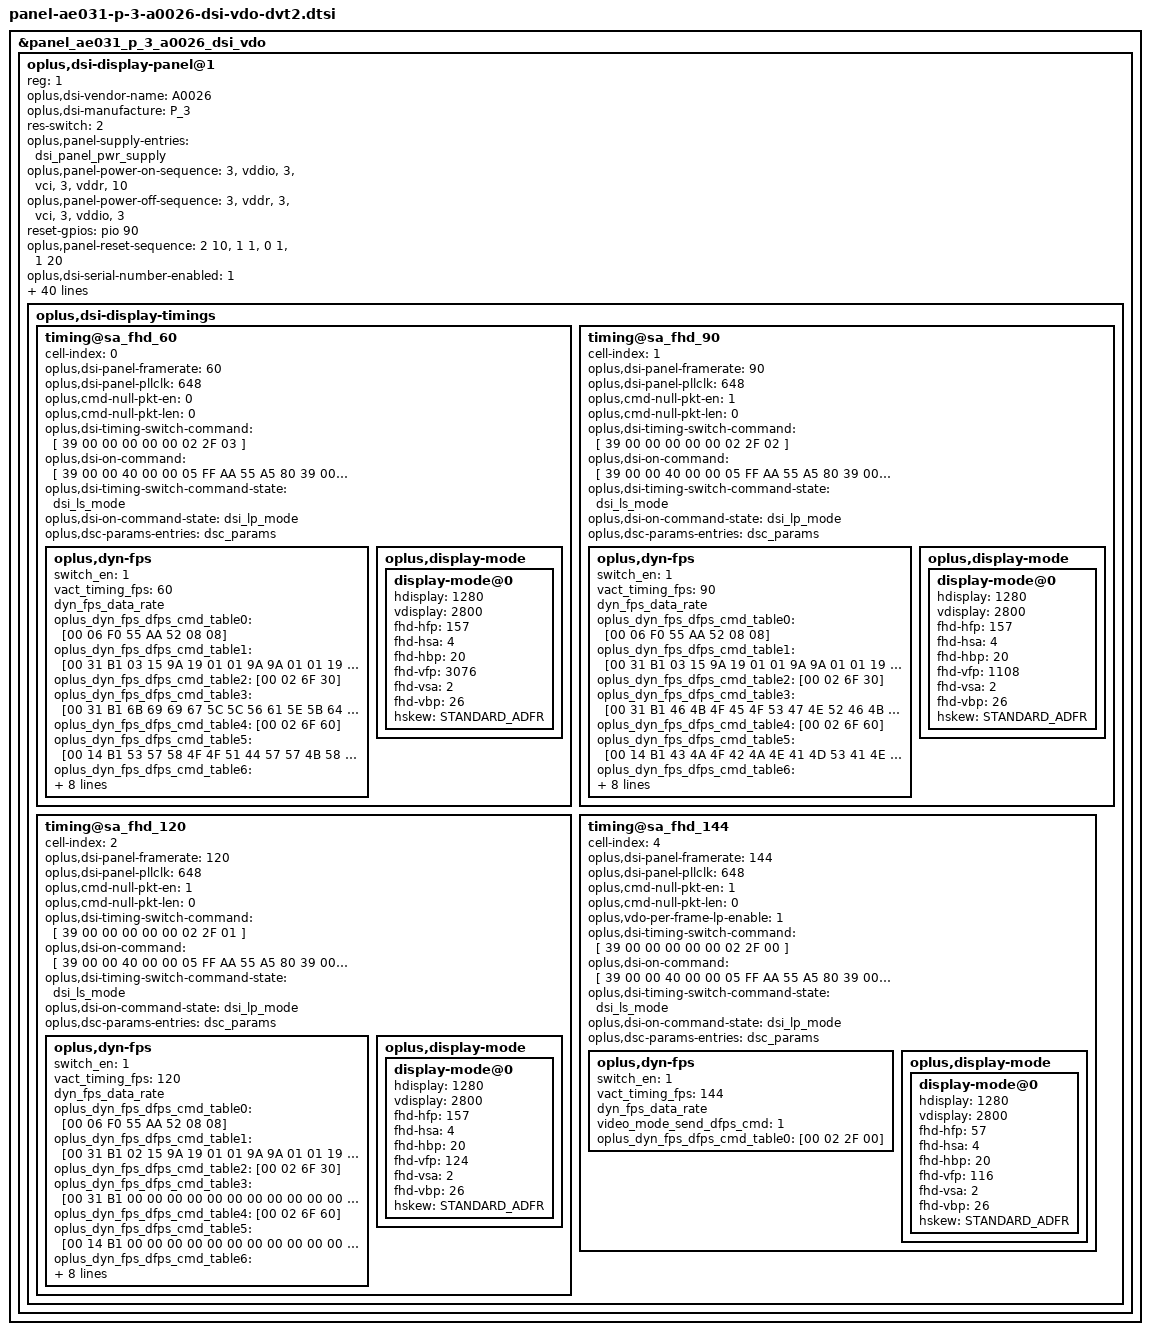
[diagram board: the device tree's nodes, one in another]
&panel_ae031_p_3_a0026_dsi_vdo {
	oplus,dsi-display-panel@1 {
		reg = <1>;
		oplus,dsi-vendor-name = "A0026";
		oplus,dsi-manufacture = "P_3";
		oplus,dsi-display-timings {
			timing@sa_fhd_60 {
				cell-index = <0>;
				oplus,dsi-panel-framerate = <60>;
				oplus,dsi-panel-pllclk = <648>;
				oplus,cmd-null-pkt-en = <0>;
				oplus,cmd-null-pkt-len = <0>;
				/* OPLUS_FEATURE_DISPLAY_ONSCREENFINGERPRINT */
				//oplus,ofp_need_keep_apart_backlight;
				#include "panel-ae031-p-3-a0026-dsi-vdo-common-dvt2.dtsi"
				oplus,dsi-timing-switch-command = [
					39 00 00 00 00 00 02 2F 03
				];

				oplus,dsi-on-command = [
					//Video trim OSC2 to 167Mhz
					//For other setting refer OP manual Ch 4.3
					39 00 00 40 00 00 05 FF AA 55 A5 80
					39 00 00 40 00 00 02 6F 0A
					39 00 00 40 00 00 02 F8 02
					39 00 00 40 00 00 06 F0 55 AA 52 08 01
					39 00 00 40 00 00 02 6F 04
					39 00 00 40 00 00 02 C3 FF
					39 00 00 40 00 00 02 6F 09
					39 00 00 40 00 00 02 C3 FF
					39 00 00 40 00 00 02 EA C0
					39 00 00 40 00 00 02 6F 11
					39 00 00 40 00 00 02 EA C0
					39 00 00 40 00 00 02 6F 07
					39 00 00 40 00 00 0B EA 01 02 01 34 01 34 01 34 04 D1
					39 00 00 40 00 00 02 6F 18
					39 00 00 40 00 00 0B EA 01 8A 01 D7 01 D7 01 D7 07 5E

					//VGXP by pad cap
					39 00 00 40 00 00 05 FF AA 55 A5 80
					39 00 00 40 00 00 02 6F 1F
					39 00 00 40 00 00 02 F4 0B
					39 00 00 40 00 00 02 6F 20
					39 00 00 40 00 00 02 F4 3F
					39 00 00 40 00 00 02 6F 08
					39 00 00 40 00 00 02 FC 03
					39 00 00 40 00 00 05 FF AA 55 A5 80
					39 00 00 40 00 00 02 6F 24
					39 00 00 00 00 00 02 F8 FF

					// For Idle enter BIST
					39 00 00 40 00 00 06 F0 55 AA 52 08 00
					39 00 00 40 00 00 02 C0 00
					39 00 00 40 00 00 06 F0 55 AA 52 08 01
					39 00 00 40 00 00 02 6F 0B
					39 00 00 40 00 00 02 D2 00
					39 00 00 40 00 00 05 FF AA 55 A5 84
					39 00 00 40 00 00 02 6F 10
					39 00 00 40 00 00 02 F8 02
					39 00 00 40 00 00 05 FF AA 55 A5 84
					39 00 00 40 00 00 02 F2 15

					//LCTC Constraint For ESD Improve
					39 00 00 40 00 00 05 FF AA 55 A5 84
					39 00 00 40 00 00 02 6F A9
					39 00 00 40 00 00 02 F4 F3

					//CUC OFF
					39 00 00 40 00 00 06 F0 55 AA 52 08 08
					39 00 00 40 00 00 02 B1 02
					//Resolution Setting
					39 00 00 40 00 00 05 2A 00 00 04 FF
					39 00 00 40 00 00 05 2B 00 00 0A EF

					//VESA1.2 10 bit 3.75 DSC Setting
					// For other refer OP manual Ch 4.4
					39 00 00 40 00 00 02 90 03
					39 00 00 40 00 00 02 6F 01
					39 00 00 40 00 00 02 90 43
					39 00 00 40 00 00 13 91 AB A8 00 28 D2 00 02 5C 04 06 00 08 02 AB 02 20 10 E0

					//Dimming OFF
					39 00 00 40 00 00 02 53 20

					//Video Mode Ext_VFP VBPF Setting
					39 00 00 40 00 00 11 3B 00 1c 00 74 00 1c 00 7C 00 1c 04 54 00 1c 00 7C
					39 00 00 40 00 00 02 6F 10
					39 00 00 40 00 00 05 3B 00 1C 00 7C

					//DPC Temperature Setting
					39 00 00 40 00 00 03 81 01 19

					//FPR1 EN
					39 00 00 40 00 00 02 88 01

					//60Hz Sleep Out
					//For other refer OP manual Ch 5.4.3
					39 00 00 40 00 00 02 2F 03

					//TE ON
					39 00 00 40 00 00 02 35 00

					//Setting Loading Effect x1.0
					39 00 00 40 00 00 03 5F 00 00

					39 00 00 40 00 00 06 F0 55 AA 52 08 00
					39 00 00 40 00 00 02 6F 03
					39 00 00 40 00 00 02 B5 D5

					//Switch DBV to 0560
					39 00 00 00 00 00 03 51 05 60
					05 00 00 00 78 00 01 11 // Sleep out
					05 00 00 00 00 00 01 29 // Display out
				];

				oplus,dsi-timing-switch-command-state = "dsi_ls_mode";
				oplus,dsi-on-command-state = "dsi_lp_mode";

				oplus,dsc-params-entries = <&dsc_params>;
				oplus,dyn-fps {
					switch_en = <1>;
					vact_timing_fps = <60>;
					dyn_fps_data_rate;
					oplus_dyn_fps_dfps_cmd_table0 = [00 06 F0 55 AA 52 08 08];
					oplus_dyn_fps_dfps_cmd_table1 = [00 31 B1 03 15 9A 19 01 01 9A 9A 01 01 19 19 20 20 4E 30 01 82 43 82 40 84 40 00 00 00 00 10 F1 E2 F1 E2 FF 44 4A 45 59 00 13 10 64 64 5F 6B 6A 67 6C 6B];
					oplus_dyn_fps_dfps_cmd_table2 = [00 02 6F 30];
					oplus_dyn_fps_dfps_cmd_table3 = [00 31 B1 6B 69 69 67 5C 5C 56 61 5E 5B 64 62 5F 60 5E 5C 5A 58 55 5C 5B 56 5C 5B 57 56 54 51 55 53 4D 55 52 50 54 52 4E 5D 5C 54 53 51 49 57 57 4E 5B 5B];
					oplus_dyn_fps_dfps_cmd_table4 = [00 02 6F 60];
					oplus_dyn_fps_dfps_cmd_table5 = [00 14 B1 53 57 58 4F 4F 51 44 57 57 4B 58 58 4C 54 54 48 00 00 00];
					oplus_dyn_fps_dfps_cmd_table6 = [00 31 B2 1F 1A 21 20 1C 26 24 1F 26 27 22 29 14 0E 17 13 0E 14 10 09 13 09 03 0C 1D 19 21 23 21 21 22 1F 23 24 22 21 1F 18 1E 20 1A 1F 21 1D 22 20 1A 1E];
					oplus_dyn_fps_dfps_cmd_table7 = [00 02 6F 30];
					oplus_dyn_fps_dfps_cmd_table8 = [00 1C B2 21 1C 1F 21 1F 1D 23 22 1F 22 1F 1C 27 26 1F 29 29 1F 23 24 19 25 25 1B 00 00 00];
					oplus_dyn_fps_dfps_cmd_table9 = [00 06 F0 55 AA 52 08 08];
					oplus_dyn_fps_dfps_cmd_table10 = [00 02 B1 02];
					oplus_dyn_fps_dfps_cmd_table11 = [00 02 2F 03];
				};
				oplus,display-mode {
					display-mode@0 {
						hdisplay = <1280>;
						vdisplay = <2800>;
						fhd-hfp = <157>;
						fhd-hsa = <4>;
						fhd-hbp = <20>;
						fhd-vfp = <3076>;
						fhd-vsa = <2>;
						fhd-vbp = <26>;
						hskew = <STANDARD_ADFR>;
					};
					//display-mode@1 {
					//	hdisplay = <1080>;
					//	vdisplay = <2376>;
					//	fhd-hfp = <9>;
					//	fhd-hsa = <2>;
					//	fhd-hbp = <21>;
					//	fhd-vfp = <52>;
					//	fhd-vsa = <14>;
					//	fhd-vbp = <22>;
					//	hskew = <STANDARD_ADFR>;
					//};
					};
				};
			timing@sa_fhd_90 {
				cell-index = <1>;
				oplus,dsi-panel-framerate = <90>;
				oplus,dsi-panel-pllclk = <648>;
				oplus,cmd-null-pkt-en = <1>;
				oplus,cmd-null-pkt-len = <0>;
				/* OPLUS_FEATURE_DISPLAY_ONSCREENFINGERPRINT */
				//oplus,ofp_need_keep_apart_backlight;
				#include "panel-ae031-p-3-a0026-dsi-vdo-common-dvt2.dtsi"
				oplus,dsi-timing-switch-command = [
					39 00 00 00 00 00 02 2F 02
				];

				oplus,dsi-on-command = [
					//Video trim OSC2 to 167Mhz
					//For other setting refer OP manual Ch 4.3
					39 00 00 40 00 00 05 FF AA 55 A5 80
					39 00 00 40 00 00 02 6F 0A
					39 00 00 40 00 00 02 F8 02
					39 00 00 40 00 00 06 F0 55 AA 52 08 01
					39 00 00 40 00 00 02 6F 04
					39 00 00 40 00 00 02 C3 FF
					39 00 00 40 00 00 02 6F 09
					39 00 00 40 00 00 02 C3 FF
					39 00 00 40 00 00 02 EA C0
					39 00 00 40 00 00 02 6F 11
					39 00 00 40 00 00 02 EA C0
					39 00 00 40 00 00 02 6F 07
					39 00 00 40 00 00 0B EA 01 02 01 34 01 34 01 34 04 D1
					39 00 00 40 00 00 02 6F 18
					39 00 00 40 00 00 0B EA 01 8A 01 D7 01 D7 01 D7 07 5E

					//VGXP by pad cap
					39 00 00 40 00 00 05 FF AA 55 A5 80
					39 00 00 40 00 00 02 6F 1F
					39 00 00 40 00 00 02 F4 0B
					39 00 00 40 00 00 02 6F 20
					39 00 00 40 00 00 02 F4 3F
					39 00 00 40 00 00 02 6F 08
					39 00 00 40 00 00 02 FC 03
					39 00 00 40 00 00 05 FF AA 55 A5 80
					39 00 00 40 00 00 02 6F 24
					39 00 00 00 00 00 02 F8 FF

					// For Idle enter BIST
					39 00 00 40 00 00 06 F0 55 AA 52 08 00
					39 00 00 40 00 00 02 C0 00
					39 00 00 40 00 00 06 F0 55 AA 52 08 01
					39 00 00 40 00 00 02 6F 0B
					39 00 00 40 00 00 02 D2 00
					39 00 00 40 00 00 05 FF AA 55 A5 84
					39 00 00 40 00 00 02 6F 10
					39 00 00 40 00 00 02 F8 02
					39 00 00 40 00 00 05 FF AA 55 A5 84
					39 00 00 40 00 00 02 F2 15

					//LCTC Constraint For ESD Improve
					39 00 00 40 00 00 05 FF AA 55 A5 84
					39 00 00 40 00 00 02 6F A9
					39 00 00 40 00 00 02 F4 F3

					//CUC OFF
					39 00 00 40 00 00 06 F0 55 AA 52 08 08
					39 00 00 40 00 00 02 B1 02
					//Resolution Setting
					39 00 00 40 00 00 05 2A 00 00 04 FF
					39 00 00 40 00 00 05 2B 00 00 0A EF

					//VESA1.2 10 bit 3.75 DSC Setting
					// For other refer OP manual Ch 4.4
					39 00 00 40 00 00 02 90 03
					39 00 00 40 00 00 02 6F 01
					39 00 00 40 00 00 02 90 43
					39 00 00 40 00 00 13 91 AB A8 00 28 D2 00 02 5C 04 06 00 08 02 AB 02 20 10 E0

					//Dimming OFF
					39 00 00 40 00 00 02 53 20

					//Video Mode Ext_VFP VBPF Setting
					39 00 00 40 00 00 11 3B 00 1c 00 74 00 1c 00 7C 00 1c 04 54 00 1c 00 7C
					39 00 00 40 00 00 02 6F 10
					39 00 00 40 00 00 05 3B 00 1C 00 7C

					//DPC Temperature Setting
					39 00 00 40 00 00 03 81 01 19

					//FPR1 EN
					39 00 00 40 00 00 02 88 01

					//90Hz Sleep Out
					//For other refer OP manual Ch 5.4.3
					39 00 00 40 00 00 02 2F 02

					//TE ON
					39 00 00 40 00 00 02 35 00

					//Setting Loading Effect x1.0
					39 00 00 40 00 00 03 5F 00 00

					39 00 00 40 00 00 06 F0 55 AA 52 08 00
					39 00 00 40 00 00 02 6F 03
					39 00 00 40 00 00 02 B5 D5

					//Switch DBV to 0560
					39 00 00 00 00 00 03 51 05 60
					05 00 00 00 78 00 01 11 // Sleep out
					05 00 00 00 00 00 01 29 // Display out
				];

				oplus,dsi-timing-switch-command-state = "dsi_ls_mode";
				oplus,dsi-on-command-state = "dsi_lp_mode";

				oplus,dsc-params-entries = <&dsc_params>;
				oplus,dyn-fps {
					switch_en = <1>;
					vact_timing_fps = <90>;
					dyn_fps_data_rate;
					oplus_dyn_fps_dfps_cmd_table0 = [00 06 F0 55 AA 52 08 08];
					oplus_dyn_fps_dfps_cmd_table1 = [00 31 B1 03 15 9A 19 01 01 9A 9A 01 01 19 19 20 20 36 30 01 82 43 82 40 84 40 00 00 00 00 10 F1 E2 F1 E2 FF 44 4A 45 59 00 13 10 4B 50 43 50 55 48 4D 4F];
					oplus_dyn_fps_dfps_cmd_table2 = [00 02 6F 30];
					oplus_dyn_fps_dfps_cmd_table3 = [00 31 B1 46 4B 4F 45 4F 53 47 4E 52 46 4B 4E 45 4F 51 48 4B 4D 44 4E 51 46 47 4B 41 47 4B 3F 46 4C 3D 42 44 3C 47 49 3F 4B 4D 43 4C 4E 42 47 4B 3F 4D 52];
					oplus_dyn_fps_dfps_cmd_table4 = [00 02 6F 60];
					oplus_dyn_fps_dfps_cmd_table5 = [00 14 B1 43 4A 4F 42 4A 4E 41 4D 53 41 4E 52 42 4B 50 3F 00 00 00];
					oplus_dyn_fps_dfps_cmd_table6 = [00 31 B2 33 33 33 33 33 33 33 33 33 33 33 33 33 33 33 33 33 33 33 33 33 33 33 33 36 36 36 36 36 36 36 36 36 36 36 36 36 36 36 36 36 36 36 36 36 36 36 36];
					oplus_dyn_fps_dfps_cmd_table7 = [00 02 6F 30];
					oplus_dyn_fps_dfps_cmd_table8 = [00 1C B2 36 36 36 36 36 36 36 36 36 36 36 36 36 36 36 36 36 36 36 36 36 36 36 36 00 00 00];
					oplus_dyn_fps_dfps_cmd_table9 = [00 06 F0 55 AA 52 08 08];
					oplus_dyn_fps_dfps_cmd_table10 = [00 02 B1 02];
					oplus_dyn_fps_dfps_cmd_table11 = [00 02 2F 02];
				};
				oplus,display-mode {
					display-mode@0 {
						hdisplay = <1280>;
						vdisplay = <2800>;
						fhd-hfp = <157>;
						fhd-hsa = <4>;
						fhd-hbp = <20>;
						fhd-vfp = <1108>;
						fhd-vsa = <2>;
						fhd-vbp = <26>;
						hskew = <STANDARD_ADFR>;
					};
					//isplay-mode@1 {
					//	hdisplay = <1080>;
					//	vdisplay = <2376>;
					//	fhd-hfp = <9>;
					//	fhd-hsa = <2>;
					//	fhd-hbp = <21>;
					//	fhd-vfp = <52>;
					//	fhd-vsa = <14>;
					//	fhd-vbp = <22>;
					//	hskew = <STANDARD_ADFR>;
					//;
				};
			};
			timing@sa_fhd_120 {
				cell-index = <2>;
				oplus,dsi-panel-framerate = <120>;
				oplus,dsi-panel-pllclk = <648>;
				oplus,cmd-null-pkt-en = <1>;
				oplus,cmd-null-pkt-len = <0>;
				/* OPLUS_FEATURE_DISPLAY_ONSCREENFINGERPRINT */
				//oplus,ofp_need_keep_apart_backlight;
				#include "panel-ae031-p-3-a0026-dsi-vdo-common-dvt2.dtsi"
				oplus,dsi-timing-switch-command = [
					39 00 00 00 00 00 02 2F 01
				];

				oplus,dsi-on-command = [
					//Video trim OSC2 to 167Mhz
					//For other setting refer OP manual Ch 4.3
					39 00 00 40 00 00 05 FF AA 55 A5 80
					39 00 00 40 00 00 02 6F 0A
					39 00 00 40 00 00 02 F8 02
					39 00 00 40 00 00 06 F0 55 AA 52 08 01
					39 00 00 40 00 00 02 6F 04
					39 00 00 40 00 00 02 C3 FF
					39 00 00 40 00 00 02 6F 09
					39 00 00 40 00 00 02 C3 FF
					39 00 00 40 00 00 02 EA C0
					39 00 00 40 00 00 02 6F 11
					39 00 00 40 00 00 02 EA C0
					39 00 00 40 00 00 02 6F 07
					39 00 00 40 00 00 0B EA 01 02 01 34 01 34 01 34 04 D1
					39 00 00 40 00 00 02 6F 18
					39 00 00 40 00 00 0B EA 01 8A 01 D7 01 D7 01 D7 07 5E

					//VGXP by pad cap
					39 00 00 40 00 00 05 FF AA 55 A5 80
					39 00 00 40 00 00 02 6F 1F
					39 00 00 40 00 00 02 F4 0B
					39 00 00 40 00 00 02 6F 20
					39 00 00 40 00 00 02 F4 3F
					39 00 00 40 00 00 02 6F 08
					39 00 00 40 00 00 02 FC 03
					39 00 00 40 00 00 05 FF AA 55 A5 80
					39 00 00 40 00 00 02 6F 24
					39 00 00 00 00 00 02 F8 FF

					// For Idle enter BIST
					39 00 00 40 00 00 06 F0 55 AA 52 08 00
					39 00 00 40 00 00 02 C0 00
					39 00 00 40 00 00 06 F0 55 AA 52 08 01
					39 00 00 40 00 00 02 6F 0B
					39 00 00 40 00 00 02 D2 00
					39 00 00 40 00 00 05 FF AA 55 A5 84
					39 00 00 40 00 00 02 6F 10
					39 00 00 40 00 00 02 F8 02
					39 00 00 40 00 00 05 FF AA 55 A5 84
					39 00 00 40 00 00 02 F2 15

					//LCTC Constraint For ESD Improve
					39 00 00 40 00 00 05 FF AA 55 A5 84
					39 00 00 40 00 00 02 6F A9
					39 00 00 40 00 00 02 F4 F3

					//CUC OFF
					39 00 00 40 00 00 06 F0 55 AA 52 08 08
					39 00 00 40 00 00 02 B1 02
					//Resolution Setting
					39 00 00 40 00 00 05 2A 00 00 04 FF
					39 00 00 40 00 00 05 2B 00 00 0A EF

					//VESA1.2 10 bit 3.75 DSC Setting
					// For other refer OP manual Ch 4.4
					39 00 00 40 00 00 02 90 03
					39 00 00 40 00 00 02 6F 01
					39 00 00 40 00 00 02 90 43
					39 00 00 40 00 00 13 91 AB A8 00 28 D2 00 02 5C 04 06 00 08 02 AB 02 20 10 E0

					//Dimming OFF
					39 00 00 40 00 00 02 53 20

					//Video Mode Ext_VFP VBPF Setting
					39 00 00 40 00 00 11 3B 00 1c 00 74 00 1c 00 7C 00 1c 04 54 00 1c 00 7C
					39 00 00 40 00 00 02 6F 10
					39 00 00 40 00 00 05 3B 00 1C 00 7C

					//DPC Temperature Setting
					39 00 00 40 00 00 03 81 01 19

					//FPR1 EN
					39 00 00 40 00 00 02 88 01

					//120Hz Sleep Out
					//For other refer OP manual Ch 5.4.3
					39 00 00 40 00 00 02 2F 01

					//TE ON
					39 00 00 40 00 00 02 35 00

					//Setting Loading Effect x1.0
					39 00 00 40 00 00 03 5F 00 00

					39 00 00 40 00 00 06 F0 55 AA 52 08 00
					39 00 00 40 00 00 02 6F 03
					39 00 00 40 00 00 02 B5 D5

					//Switch DBV to 0560
					39 00 00 00 00 00 03 51 05 60
					05 00 00 00 78 00 01 11 // Sleep out
					05 00 00 00 00 00 01 29 // Display out
				];

				oplus,dsi-timing-switch-command-state = "dsi_ls_mode";
				oplus,dsi-on-command-state = "dsi_lp_mode";

				oplus,dsc-params-entries = <&dsc_params>;
				oplus,dyn-fps {
					switch_en = <1>;
					vact_timing_fps = <120>;
					dyn_fps_data_rate;
					oplus_dyn_fps_dfps_cmd_table0 = [00 06 F0 55 AA 52 08 08];
					oplus_dyn_fps_dfps_cmd_table1 = [00 31 B1 02 15 9A 19 01 01 9A 9A 01 01 19 19 20 20 44 43 BF 40 D4 40 BB FF FE FF 00 00 00 10 F1 E2 F1 E2 FF 41 FD 00 1C 00 13 10 00 00 00 00 00 00 00 00];
					oplus_dyn_fps_dfps_cmd_table2 = [00 02 6F 30];
					oplus_dyn_fps_dfps_cmd_table3 = [00 31 B1 00 00 00 00 00 00 00 00 00 00 00 00 00 00 00 00 00 00 00 00 00 00 00 00 00 00 00 00 00 00 00 00 00 00 00 00 00 00 00 00 00 00 00 00 00 00 00 00];
					oplus_dyn_fps_dfps_cmd_table4 = [00 02 6F 60];
					oplus_dyn_fps_dfps_cmd_table5 = [00 14 B1 00 00 00 00 00 00 00 00 00 00 00 00 00 00 00 00 00 00 00];
					oplus_dyn_fps_dfps_cmd_table6 = [00 31 B2 00 00 00 00 00 00 00 00 00 00 00 00 00 00 00 00 00 00 00 00 00 00 00 00 00 00 00 00 00 00 00 00 00 00 00 00 00 00 00 00 00 00 00 00 00 00 00 00];
					oplus_dyn_fps_dfps_cmd_table7 = [00 02 6F 30];
					oplus_dyn_fps_dfps_cmd_table8 = [00 1C B2 00 00 00 00 00 00 00 00 00 00 00 00 00 00 00 00 00 00 00 00 00 00 00 00 00 00 00];
					oplus_dyn_fps_dfps_cmd_table9 = [00 06 F0 55 AA 52 08 08];
					oplus_dyn_fps_dfps_cmd_table10 = [00 02 B1 02];
					oplus_dyn_fps_dfps_cmd_table11 = [00 02 2F 01];
				};
				oplus,display-mode {
					display-mode@0 {
						hdisplay = <1280>;
						vdisplay = <2800>;
						fhd-hfp = <157>;
						fhd-hsa = <4>;
						fhd-hbp = <20>;
						fhd-vfp = <124>;
						fhd-vsa = <2>;
						fhd-vbp = <26>;
						hskew = <STANDARD_ADFR>;
					};
					//display-mode@1 {
					//	hdisplay = <1080>;
					//	vdisplay = <2376>;
					//	fhd-hfp = <9>;
					//	fhd-hsa = <2>;
					//	fhd-hbp = <21>;
					//	fhd-vfp = <52>;
					//	fhd-vsa = <14>;
					//	fhd-vbp = <22>;
					//	hskew = <STANDARD_ADFR>;
					//};
				};
			};
			timing@sa_fhd_144 {
				cell-index = <4>;
				oplus,dsi-panel-framerate = <144>;
				oplus,dsi-panel-pllclk = <648>;
				oplus,cmd-null-pkt-en = <1>;
				oplus,cmd-null-pkt-len = <0>;
				oplus,vdo-per-frame-lp-enable = <1>;
				/* OPLUS_FEATURE_DISPLAY_ONSCREENFINGERPRINT */
				//oplus,ofp_need_keep_apart_backlight;
				#include "panel-ae031-p-3-a0026-dsi-vdo-common.dtsi"
				oplus,dsi-timing-switch-command = [
					39 00 00 00 00 00 02 2F 00
				];

				oplus,dsi-on-command = [
					//Video trim OSC2 to 167Mhz
					//For other setting refer OP manual Ch 4.3
					39 00 00 40 00 00 05 FF AA 55 A5 80
					39 00 00 40 00 00 02 6F 0A
					39 00 00 40 00 00 02 F8 02
					39 00 00 40 00 00 06 F0 55 AA 52 08 01
					39 00 00 40 00 00 02 6F 04
					39 00 00 40 00 00 02 C3 FF
					39 00 00 40 00 00 02 6F 09
					39 00 00 40 00 00 02 C3 FF
					39 00 00 40 00 00 02 EA C0
					39 00 00 40 00 00 02 6F 11
					39 00 00 40 00 00 02 EA C0
					39 00 00 40 00 00 02 6F 07
					39 00 00 40 00 00 0B EA 01 02 01 34 01 34 01 34 04 D1
					39 00 00 40 00 00 02 6F 18
					39 00 00 40 00 00 0B EA 01 8A 01 D7 01 D7 01 D7 07 5E

					//VGXP by pad cap
					39 00 00 40 00 00 05 FF AA 55 A5 80
					39 00 00 40 00 00 02 6F 1F
					39 00 00 40 00 00 02 F4 0B
					39 00 00 40 00 00 02 6F 20
					39 00 00 40 00 00 02 F4 3F
					39 00 00 40 00 00 02 6F 08
					39 00 00 40 00 00 02 FC 03
					39 00 00 40 00 00 05 FF AA 55 A5 80
					39 00 00 40 00 00 02 6F 24
					39 00 00 00 00 00 02 F8 FF

					// For Idle enter BIST
					39 00 00 40 00 00 06 F0 55 AA 52 08 00
					39 00 00 40 00 00 02 C0 00
					39 00 00 40 00 00 06 F0 55 AA 52 08 01
					39 00 00 40 00 00 02 6F 0B
					39 00 00 40 00 00 02 D2 00
					39 00 00 40 00 00 05 FF AA 55 A5 84
					39 00 00 40 00 00 02 6F 10
					39 00 00 40 00 00 02 F8 02
					39 00 00 40 00 00 05 FF AA 55 A5 84
					39 00 00 40 00 00 02 F2 15

					//LCTC Constraint For ESD Improve
					39 00 00 40 00 00 05 FF AA 55 A5 84
					39 00 00 40 00 00 02 6F A9
					39 00 00 40 00 00 02 F4 F3

					//FOD OFF
					39 00 00 40 00 00 06 F0 55 AA 52 08 09
					39 00 00 40 00 00 02 6F 00
					39 00 00 40 00 00 02 B0 01
					39 00 00 40 00 00 02 6F 25
					39 00 00 40 00 00 02 B0 00
					39 00 00 40 00 00 03 8B 00 00
					39 00 00 00 00 00 02 87 00

					//CUC OFF
					39 00 00 40 00 00 06 F0 55 AA 52 08 08
					39 00 00 40 00 00 02 B1 02
					//Resolution Setting
					39 00 00 40 00 00 05 2A 00 00 04 FF
					39 00 00 40 00 00 05 2B 00 00 0A EF

					//VESA1.2 10 bit 3.75 DSC Setting
					// For other refer OP manual Ch 4.4
					39 00 00 40 00 00 02 90 03
					39 00 00 40 00 00 02 6F 01
					39 00 00 40 00 00 02 90 43
					39 00 00 40 00 00 13 91 AB A8 00 28 D2 00 02 5C 04 06 00 08 02 AB 02 20 10 E0

					//Dimming OFF
					39 00 00 40 00 00 02 53 20

					//Video Mode Ext_VFP VBPF Setting
					39 00 00 40 00 00 11 3B 00 1c 00 74 00 1c 00 7C 00 1c 04 54 00 1c 00 7C
					39 00 00 40 00 00 02 6F 10
					39 00 00 40 00 00 05 3B 00 1C 00 7C

					//DPC Temperature Setting
					39 00 00 40 00 00 03 81 01 19

					//FPR1 EN
					39 00 00 40 00 00 02 88 01

					//144 Hz Sleep Out
					//For other refer OP manual Ch 5.4.3
					39 00 00 40 00 00 02 2F 00

					//TE ON
					39 00 00 40 00 00 02 35 00

					//Setting Loading Effect x1.0
					39 00 00 40 00 00 03 5F 00 00

					39 00 00 40 00 00 06 F0 55 AA 52 08 00
					39 00 00 40 00 00 02 6F 03
					39 00 00 40 00 00 02 B5 D5

					//Switch DBV to 0560
					39 00 00 00 00 00 03 51 05 60
					05 00 00 00 78 00 01 11 // Sleep out
					05 00 00 00 00 00 01 29 // Display out
				];

				oplus,dsi-timing-switch-command-state = "dsi_ls_mode";
				oplus,dsi-on-command-state = "dsi_lp_mode";

				oplus,dsc-params-entries = <&dsc_params>;
				oplus,dyn-fps {
					switch_en = <1>;
					vact_timing_fps = <144>;
					dyn_fps_data_rate;
					video_mode_send_dfps_cmd = <1>;
					oplus_dyn_fps_dfps_cmd_table0 = [00 02 2F 00];
				};
				oplus,display-mode {
					display-mode@0 {
						hdisplay = <1280>;
						vdisplay = <2800>;
						fhd-hfp = <57>;
						fhd-hsa = <4>;
						fhd-hbp = <20>;
						fhd-vfp = <116>;
						fhd-vsa = <2>;
						fhd-vbp = <26>;
						hskew = <STANDARD_ADFR>;
					};
					//display-mode@1 {
					//	hdisplay = <1080>;
					//	vdisplay = <2376>;
					//	fhd-hfp = <9>;
					//	fhd-hsa = <2>;
					//	fhd-hbp = <21>;
					//	fhd-vfp = <52>;
					//	fhd-vsa = <14>;
					//	fhd-vbp = <22>;
					//	hskew = <STANDARD_ADFR>;
					//};
				};
			};
		};
	};
};

&panel_ae031_p_3_a0026_dsi_vdo {
	oplus,dsi-display-panel@1 {
		res-switch = <2>;
		/* Hardware config */
		oplus,panel-supply-entries = <&dsi_panel_pwr_supply>;
		oplus,panel-power-on-sequence = "3", "vddio", "3", "vci", "3", "vddr", "10";
		oplus,panel-power-off-sequence = "3", "vddr", "3", "vci", "3", "vddio", "3";
		reset-gpios = <&pio 90 0>;
		oplus,panel-reset-sequence = <2 10>, <1 1>, <0 1>, <1 20>;
		/* Panel config */
		oplus,dsi-serial-number-enabled = <1>;
		oplus,dsi-serial-number-switch-page;
		oplus,dsi-serial-number-index = <0>;
		oplus,dsi-serial-number-switch-page-command = <0xF0 0x55 0xAA 0x52 0x08 0x01>;
		oplus,dsi-serial-number-default-switch-page-command = <0xF0 0x55 0xAA 0x52 0x08 0x00>;
		oplus,dsi-serial-number-reg = <0xD7>;
		oplus,dsi-serial-number-read-count = <7>;
		// oplus,dsi-serial-number-year-offset = <0>;
		oplus,enhance-mipi-strength = <1>;
		oplus,backlight-check-disable;
		/*color*/
		oplus,color-vivid-status;
		oplus,color-srgb-status;
		// oplus,color-softiris-status;
		// oplus,color-dual-panel-status;
		oplus,color-dual-brightness-status;
		oplus,color-oplus-calibrate-status;
		// oplus,color-samsung-status;
		oplus,color-loading-status;
		oplus,color-2nit-status;
		// oplus,color-nature-profession-status;
		/* ESD */
		oplus,cust-esd-check = <0>;
		oplus,esd-check-enable = <1>;
		oplus,esd_check_cmd = [
			0A
			AB
		];
		oplus,esd_check_count = [
			01
			02
		];
		oplus,esd_check_value = [
			9C
			00 00
		];
		oplus,esd_check_mask = [
			FF
			07 0F
		];
		/* ext_params */
		oplus,panel-type = <0>;
		oplus,keep_ulps = <1>;
		oplus,lane-swap-en = <0>;
		oplus,lane-swap = <
			MIPITX_PHY_LANE_0 MIPITX_PHY_LANE_1 MIPITX_PHY_LANE_3 MIPITX_PHY_LANE_2 MIPITX_PHY_LANE_CK MIPITX_PHY_LANE_RX
			MIPITX_PHY_LANE_0 MIPITX_PHY_LANE_1 MIPITX_PHY_LANE_3 MIPITX_PHY_LANE_2 MIPITX_PHY_LANE_CK MIPITX_PHY_LANE_RX
		>;
		oplus,lcm-color-mode = <MTK_DRM_COLOR_MODE_DISPLAY_P3>;
		oplus,output-mode = <MTK_PANEL_DSC_SINGLE_PORT>;
		oplus,panel-bpp = <10>;
		oplus,physical-width-um = <71000>;
		oplus,physical-height-um = <156000>;

		/* vdo mode setting */
		oplus,change_fps_by_vfp_send_cmd_need_delay = <1>;
		oplus,vdo-per-frame-lp-enable = <1>;

		/* OFP config */
		oplus,ofp-fp-type = <0x240>;
		/*pwm config*/
		oplus,pwm-turbo-support = <1>;
		oplus,pwm-switch-backlight-threshold = <1087>;
		oplus,pwm-aid-switch-enable;
		oplus,pwm-onepulse-support = <1>;
		//oplus,pwm-onepulse-enabled = <0>;
		//oplus,pwm-turbo-wait-te = <1>;
	};
};
